# STM32WBAxx register map
File version: 0.1
Registers are 32-bit, read-write, reset 0x0 unless marked. A register's access mark holds for its fields unless they carry their own. Offsets are from the block's base; [hi:lo] are bit positions; {n}, {i} and the like mark numbered series.

## EXTI — External interrupt/event controller
Base 0x46022000
Same registers: SEC_EXTI 0x56022000
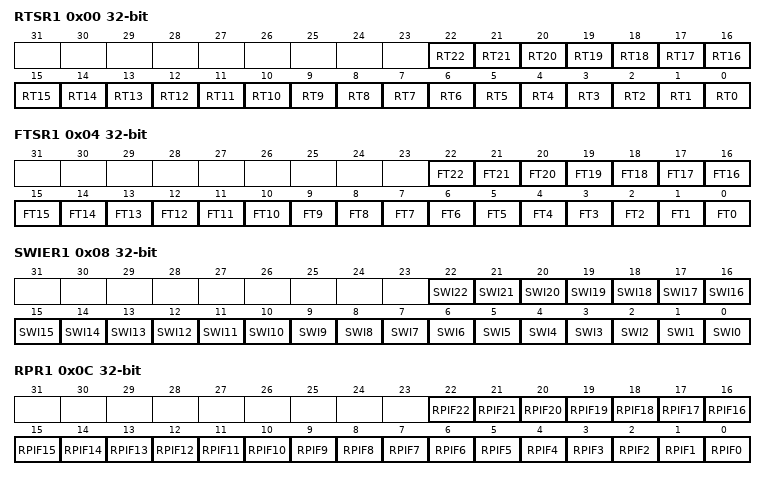
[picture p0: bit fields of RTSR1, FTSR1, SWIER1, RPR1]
0x00 RTSR1 — EXTI rising trigger selection register
  [n] RT{n} (n=0..22) — Rising trigger event configuration bit of configurable event input x
0x04 FTSR1 — EXTI falling trigger selection register
  [n] FT{n} (n=0..22) — Falling trigger event configuration bit of configurable event input x
0x08 SWIER1 — EXTI software interrupt event register
  [n] SWI{n} (n=0..22) — Software interrupt on event x
0x0C RPR1 — EXTI rising edge pending register
  [n] RPIF{n} (n=0..22) — configurable event inputs x rising edge pending bit
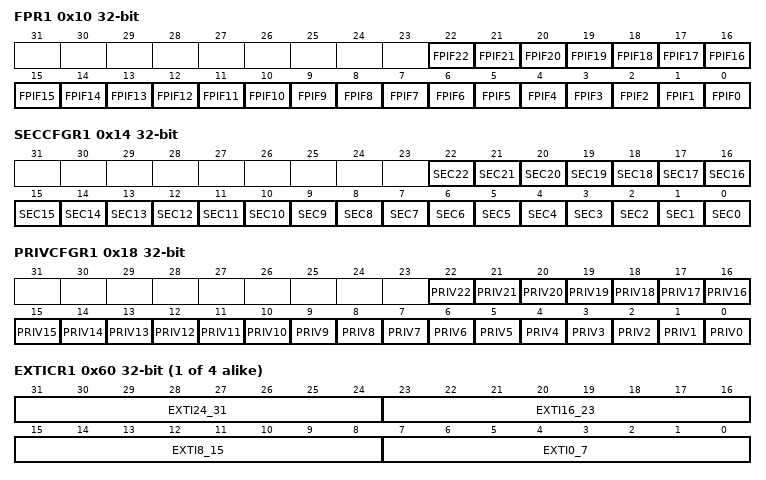
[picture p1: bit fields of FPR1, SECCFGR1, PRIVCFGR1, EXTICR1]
0x10 FPR1 — EXTI falling edge pending register
  [n] FPIF{n} (n=0..22) — configurable event inputs x falling edge pending bit.
0x14 SECCFGR1 — EXTI security configuration register
  [n] SEC{n} (n=0..22) — Security enable on event input x
0x18 PRIVCFGR1 — EXTI privilege configuration register
  [n] PRIV{n} (n=0..22) — Security enable on event input x
{0x5C+4i} EXTICR{i} (i=1..4) — EXTI external interrupt selection register
  [31:24] EXTI24_31 — EXTIm+3 GPIO port selection
  [23:16] EXTI16_23 — EXTIm+2 GPIO port selection
  [15:8] EXTI8_15 — EXTIm+1 GPIO port selection
  [7:0] EXTI0_7 — EXTIm GPIO port selection
0x70 LOCKR — EXTI lock register
  [0] LOCK
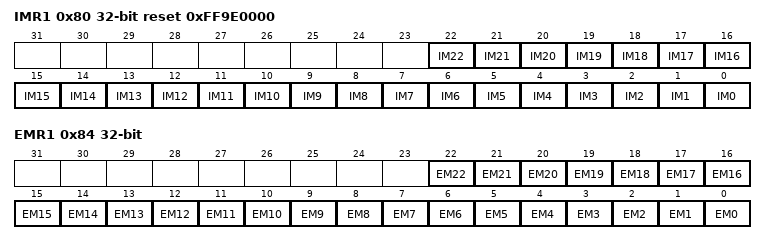
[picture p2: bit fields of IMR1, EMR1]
0x80 IMR1 reset 0xFF9E0000 — EXTI CPU wakeup with interrupt mask register
  [n] IM{n} (n=0..22) — CPU wakeup with interrupt mask on event input
0x84 EMR1 — EXTI CPU wakeup with event mask register
  [n] EM{n} (n=0..22) — CPU wakeup with event generation mask on event input

## GPIOA — General-purpose I/Os
Base 0x42020000
Same registers: SEC_GPIOA 0x52020000
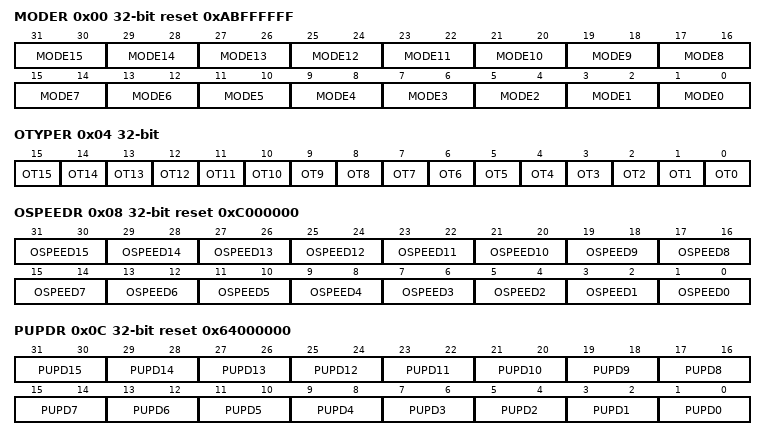
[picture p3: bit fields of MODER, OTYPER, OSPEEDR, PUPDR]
0x00 MODER reset 0xABFFFFFF — GPIO port mode register
  [2n+1:2n] MODE{n} (n=0..15) — Port x configuration bits (y = 0..15)
0x04 OTYPER — GPIO port output type register
  [n] OT{n} (n=0..15) — Port x configuration bits (y = 0..15)
0x08 OSPEEDR reset 0xC000000 — GPIO port output speed register
  [2n+1:2n] OSPEED{n} (n=0..15) — Port x configuration bits (y = 0..15)
0x0C PUPDR reset 0x64000000 — GPIO port pull-up/pull-down register
  [2n+1:2n] PUPD{n} (n=0..15) — Port x configuration bits (y = 0..15)
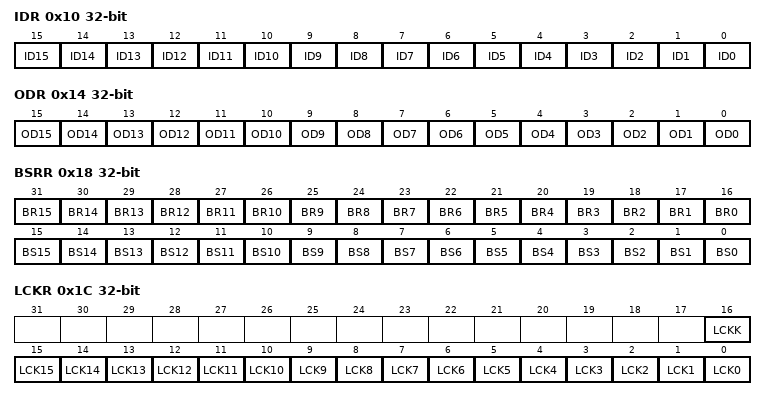
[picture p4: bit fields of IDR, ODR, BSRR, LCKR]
0x10 IDR ro — GPIO port input data register
  [n] ID{n} (n=0..15) — Port input data (y = 0..15)
0x14 ODR — GPIO port output data register
  [n] OD{n} (n=0..15) — Port output data (y = 0..15)
0x18 BSRR wo — GPIO port bit set/reset register
  [n+16] BR{n} (n=1..15) — Port x reset bit y (y = 0..15)
  [16] BR0 — Port x set bit y (y= 0..15)
  [n] BS{n} (n=0..15) — Port x set bit y (y= 0..15)
0x1C LCKR — GPIO port configuration lock register
  [16] LCKK — Lock key
  [n] LCK{n} (n=0..15) — Port x lock bit y (y= 0..15)
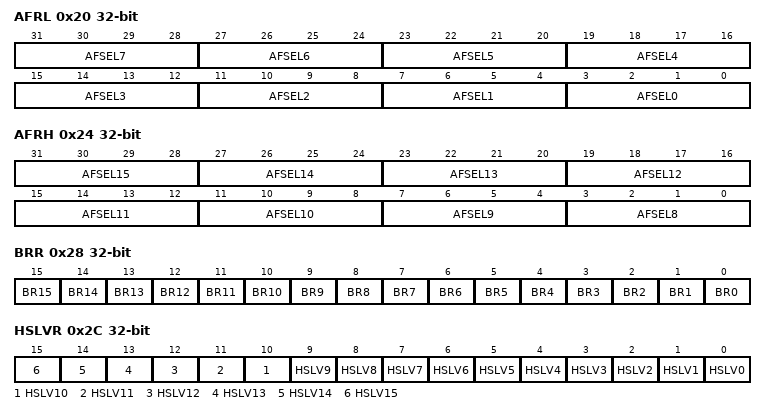
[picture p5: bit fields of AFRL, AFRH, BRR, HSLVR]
0x20 AFRL — GPIO alternate function low register
  [4n+3:4n] AFSEL{n} (n=0..7) — Alternate function selection for port x bit y (y = 0..7)
0x24 AFRH — GPIO alternate function high register
  [4n-29:4n-32] AFSEL{n} (n=8..15) — Alternate function selection for port x bit y (y = 8..15)
0x28 BRR wo — GPIO port bit reset register
  [n] BR{n} (n=0..15) — Port x reset IO pin y
0x2C HSLVR — GPIO high-speed low-voltage register
  [n] HSLV{n} (n=0..15) — Port x high-speed low-voltage configuration (y= 15 to 0)
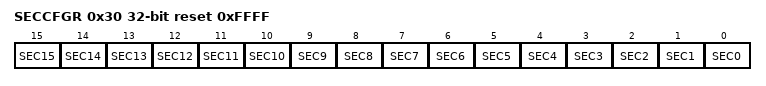
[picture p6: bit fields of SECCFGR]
0x30 SECCFGR wo reset 0xFFFF — GPIO secure configuration register
  [n] SEC{n} (n=0..15) — I/O pin of Port x secure bit enable

## GPIOB — General-purpose I/Os
Base 0x42020400
Same registers: SEC_GPIOB 0x52020400
Registers as GPIOA; these are added or differ:
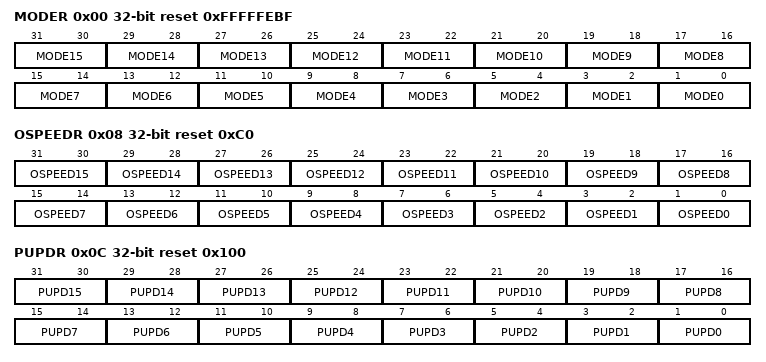
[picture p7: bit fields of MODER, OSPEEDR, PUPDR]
0x00 MODER reset 0xFFFFFEBF — GPIO port mode register
  [2n+1:2n] MODE{n} (n=0..15) — Port x configuration bits (y = 0..15)
0x08 OSPEEDR reset 0xC0 — GPIO port output speed register
  [2n+1:2n] OSPEED{n} (n=0..15) — Port x configuration bits (y = 0..15)
0x0C PUPDR reset 0x100 — GPIO port pull-up/pull-down register
  [2n+1:2n] PUPD{n} (n=0..15) — Port x configuration bits (y = 0..15)

## GPIOC — General-purpose I/Os
Base 0x42020800
Same registers: GPIOD 0x42020C00, GPIOE 0x42021000, GPIOF 0x42021400, GPIOG 0x42021800, GPIOH 0x42021C00, SEC_GPIOC 0x52020800, SEC_GPIOD 0x52020C00, SEC_GPIOE 0x52021000, SEC_GPIOF 0x52021400, SEC_GPIOG 0x52021800, SEC_GPIOH 0x52021C00
Registers as GPIOA; these are added or differ:
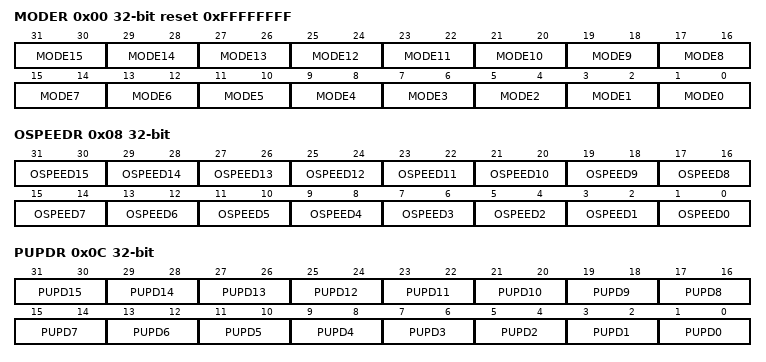
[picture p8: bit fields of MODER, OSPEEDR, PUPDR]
0x00 MODER reset 0xFFFFFFFF — GPIO port mode register
  [2n+1:2n] MODE{n} (n=0..15) — Port x configuration bits (y = 0..15)
0x08 OSPEEDR — GPIO port output speed register
  [2n+1:2n] OSPEED{n} (n=0..15) — Port x configuration bits (y = 0..15)
0x0C PUPDR — GPIO port pull-up/pull-down register
  [2n+1:2n] PUPD{n} (n=0..15) — Port x configuration bits (y = 0..15)
